# ATtiny40 device description
Architecture: AVR8L; Family: tinyAVR
Programming and debug interfaces: TPI
Registers are 8-bit, access not given, no defined reset value unless marked. A register's access mark holds for its fields unless they carry their own. Offsets are from the block's base; lines under a group give offsets from that group; [hi:lo] are bit positions; {n}, {i} and the like mark numbered series; 'fields as' and 'values as' point back to an identical list; <NAME> marks a mode.

## Ordering variants
ATtiny40-SU: SOIC20, pinout DIP, up to 12 MHz, -40 to 85 C, 1.8 to 5.5 V
ATtiny40-XU: TSSOP20, pinout DIP, up to 12 MHz, -40 to 85 C, 1.8 to 5.5 V
ATtiny40-MMH: VQFN20, pinout VQFN, up to 12 MHz, -40 to 85 C, 1.8 to 5.5 V

## Memory
prog space: start 0x0000 size 0x1000, little endian
  0x0000 FLASH size 0x1000 flash, rw, executable, page 0x80
signatures space: start 0 size 3, little endian
  0 SIGNATURES size 3 signatures, ro
fuses space: start 0 size 0x0001, little endian
  0 FUSES size 0x0001 fuses, rw
lockbits space: start 0 size 0x0001, little endian
  0 LOCKBITS size 0x0001 lockbits, rw
data space: start 0x0000 size 0x5000, little endian
  0x0000 IO size 0x40 io
  0x0040 SRAM size 0x100 ram
  0x3F00 MAPPED_NVM_LOCK_BITS size 0x0002 sysreg
  0x3F40 MAPPED_CONFIGURATION_BITS size 0x0002 sysreg
  0x3F80 MAPPED_CALIBRATION_BITS size 0x0002 sysreg
  0x3FC0 MAPPED_DEVICE_ID_BITS size 0x0004 sysreg
  0x4000 MAPPED_FLASH size 0x1000 flash
osccal space: start 0 size 1, little endian
  0 OSCCAL size 1 osccal, ro

## Peripheral instances (address, pins/pin function, parameters)
WDT at 0x00 — Watchdog Timer
ADC at 0x00 — Analog-to-Digital Converter
  pins: ADC{n} PA{n} (n=0..7); ADC8 PB0; ADC9 PB1; ADC10 PB2; ADC11 PB3
AC at 0x00 — Analog Comparator
  pins: AIN0 PA1; AIN1 PA2
TWI at 0x00 — Two Wire Serial Interface
  pins: SCL PC1; SDA PC4
CPU at 0x00 — CPU Registers
  parameters: CORE_VERSION=AVR8L_0
EXINT at 0x00 — External Interrupts
  pins: PCINT{n} PA{n} (n=0..7); PCINT8 PB0; PCINT9 PB1; PCINT10 PB2; PCINT11 PB3; PCINT12 PC0; PCINT13 PC1; PCINT14 PC2; PCINT15 PC3; PCINT16 PC4; PCINT17 PC5; INT0 PC2
PORTB at 0x00 — I/O Port
  pins: P0 PB0; P1 PB1; P2 PB2; P3 PB3
PORTC at 0x00 — I/O Port
  pins: P0 PC0; P1 PC1; P2 PC2; P3 PC3; P4 PC4; P5 PC5
PORTA at 0x00 — I/O Port
  pins: P{n} PA{n} (n=0..7)
TC0 at 0x00 — Timer/Counter, 8-bit
  pins: T PA4; OCB PA5; OCA PC0
SPI at 0x00 — Serial Peripheral Interface
  pins: SS PC0; SCK PC1; MISO PC2; MOSI PC4
FUSE at 0 in fuses — Fuses
LOCKBIT at 0 in lockbits — Lockbits

## Interrupts
0 RESET — External Reset, Power-on Reset and Watchdog Reset
1 INT0 — External Interrupt Request 0
2 PCINT0 — Pin Change Interrupt Request 0
3 PCINT1 — Pin Change Interrupt Request 1
4 PCINT2 — Pin Change Interrupt Request 2
5 WDT — Watchdog Time-out
6 TIM1_CAPT — Timer/Counter1 Input Capture
7 TIM1_COMPA — Timer/Counter1 Compare Match A
8 TIM1_COMPB — Timer/Counter1 Compare Match B
9 TIM1_OVF — Timer/Counter1 Overflow
10 TIM0_COMPA — Timer/Counter0 Compare Match A
11 TIM0_COMPB — Timer/Counter0 Compare Match B
12 TIM0_OVF — Timer/Counter0 Overflow
13 ANA_COMP — Analog Comparator
14 ADC — Conversion Complete
15 TWI_SLAVE — Two-Wire Interface
16 SPI — Serial Peripheral Interface
17 QTRIP — Touch Sensing

## Properties
SIGNATURES: SIGNATURE0=0x1e, SIGNATURE1=0x92, SIGNATURE2=0x0e

## Pinouts (pin number, pad)
DIP: 1 PB0, 2 PA7, 3 PA6, 4 PA5, 5 PA4, 6 PA3, 7 PA2, 8 PA1, 9 PA0, 10 GND, 11 VCC, 12 PC5, 13 PC4, 14 PC3, 15 PC2, 16 PC1, 17 PC0, 18 PB3, 19 PB2, 20 PB1
VQFN: 1 PA6, 2 PA5, 3 PA4, 4 PA3, 5 PA2, 6 PA1, 7 PA0, 8 GND, 9 VCC, 10 PC5, 11 PC4, 12 PC3, 13 PC2, 14 PC1, 15 PC0, 16 PB3, 17 PB2, 18 PB1, 19 PB0, 20 PA7

## FUSE — Fuses
Instances: FUSE 0 in fuses
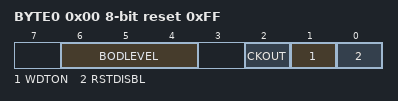
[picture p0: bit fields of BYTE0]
0x00 BYTE0 reset 0xFF
  [6:4] BODLEVEL — Brown-out Detector trigger level
    7=DISABLED (Brown-out detection disabled; [BODLEVEL=111]); 6=1V8 (Brown-out detection at VCC=1.8 V); 5=2V7 (Brown-out detection at VCC=2.7 V); 4=4V3 (Brown-out detection at VCC=4.3 V)
  [2] CKOUT — Output external clock
  [1] WDTON — Watch dog timer always on
  [0] RSTDISBL — Disable external reset
